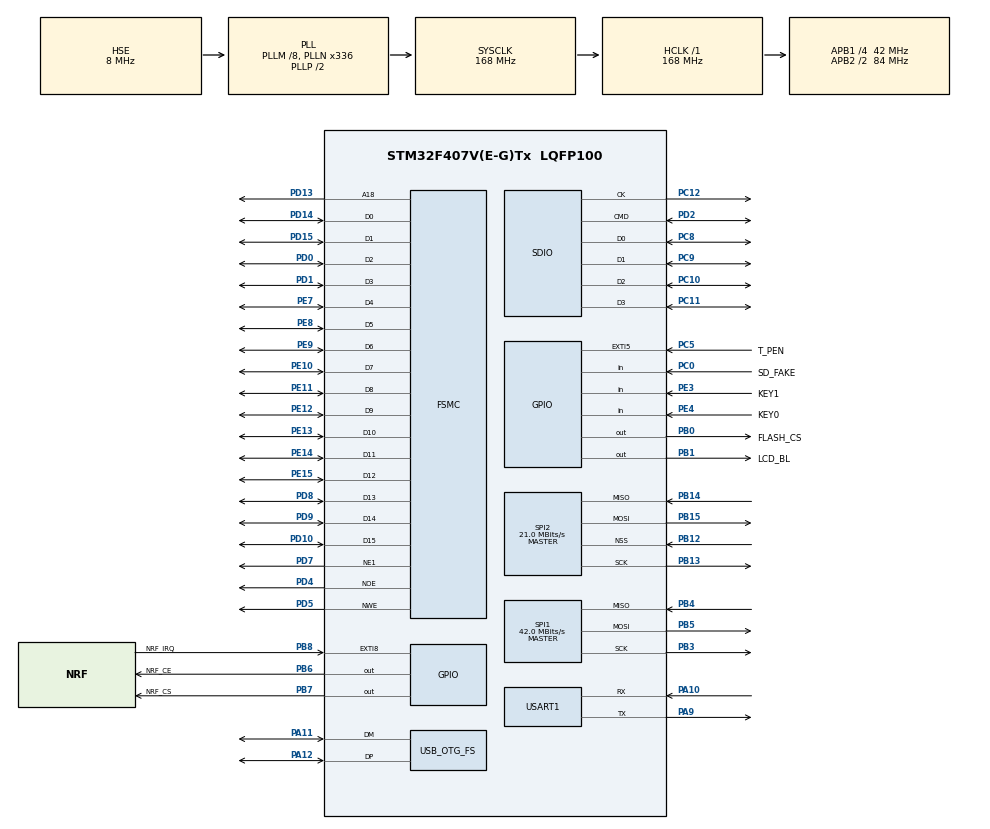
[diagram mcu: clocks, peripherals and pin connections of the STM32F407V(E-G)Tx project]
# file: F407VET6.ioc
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Dma.Request0=SDIO
Dma.SDIO.0.Direction=DMA_PERIPH_TO_MEMORY
Dma.SDIO.0.FIFOMode=DMA_FIFOMODE_ENABLE
Dma.SDIO.0.FIFOThreshold=DMA_FIFO_THRESHOLD_FULL
Dma.SDIO.0.Instance=DMA2_Stream3
Dma.SDIO.0.MemBurst=DMA_MBURST_INC4
Dma.SDIO.0.MemDataAlignment=DMA_MDATAALIGN_WORD
Dma.SDIO.0.MemInc=DMA_MINC_ENABLE
Dma.SDIO.0.Mode=DMA_PFCTRL
Dma.SDIO.0.PeriphBurst=DMA_PBURST_INC4
Dma.SDIO.0.PeriphDataAlignment=DMA_PDATAALIGN_WORD
Dma.SDIO.0.PeriphInc=DMA_PINC_DISABLE
Dma.SDIO.0.Priority=DMA_PRIORITY_LOW
FATFS.BSP.number=1
FATFS0.BSP.STBoard=false
FATFS0.BSP.api=Unknown
FATFS0.BSP.instance=PC0
FATFS0.BSP.ip=GPIO
FATFS0.BSP.mode=Input
FATFS0.BSP.name=Detect_SDIO
FATFS0.BSP.solution=PC0
FSMC.BusTurnAroundDuration1=0
FSMC.DataSetupTime1=13
FSMC.ExtendedMode1=FSMC_EXTENDED_MODE_DISABLE
Mcu.Family=STM32F4
Mcu.Name=STM32F407V(E-G)Tx
Mcu.Package=LQFP100
NVIC.DMA2_Stream3_IRQn=true\:0\:0\:false\:false\:true\:false\:true\:true
NVIC.OTG_FS_IRQn=true\:0\:0\:false\:false\:true\:false\:true\:true
NVIC.PriorityGroup=NVIC_PRIORITYGROUP_4
NVIC.RTC_Alarm_IRQn=true\:0\:0\:false\:false\:true\:true\:true\:true
NVIC.SDIO_IRQn=true\:0\:0\:false\:false\:true\:true\:true\:true
PA10.Mode=Asynchronous
PA10.Signal=USART1_RX
PA11.Mode=Device_Only
PA11.Signal=USB_OTG_FS_DM
PA12.Mode=Device_Only
PA12.Signal=USB_OTG_FS_DP
PA13.Mode=Serial_Wire
PA13.Signal=SYS_JTMS-SWDIO
PA14.Mode=Serial_Wire
PA14.Signal=SYS_JTCK-SWCLK
PA9.Mode=Asynchronous
PA9.Signal=USART1_TX
PB0.GPIO_Label=FLASH_CS
PB0.Signal=GPIO_Output
PB1.GPIO_Label=LCD_BL
PB1.PinState=GPIO_PIN_SET
PB1.Signal=GPIO_Output
PB12.Mode=NSS_Signal_Hard_Input
PB12.Signal=SPI2_NSS
PB13.Mode=Full_Duplex_Master
PB13.Signal=SPI2_SCK
PB14.Mode=Full_Duplex_Master
PB14.Signal=SPI2_MISO
PB15.Mode=Full_Duplex_Master
PB15.Signal=SPI2_MOSI
PB3.Mode=Full_Duplex_Master
PB3.Signal=SPI1_SCK
PB4.Mode=Full_Duplex_Master
PB4.Signal=SPI1_MISO
PB5.Mode=Full_Duplex_Master
PB5.Signal=SPI1_MOSI
PB6.GPIO_Label=NRF_CE
PB6.Signal=GPIO_Output
PB7.GPIO_Label=NRF_CS
PB7.Signal=GPIO_Output
PB8.GPIO_Label=NRF_IRQ
PB8.Signal=GPXTI8
PC0.GPIO_Label=SD_FAKE
PC0.GPIO_PuPd=GPIO_PULLUP
PC0.Signal=GPIO_Input
PC10.Mode=SD_4_bits_Wide_bus
PC10.Signal=SDIO_D2
PC11.Mode=SD_4_bits_Wide_bus
PC11.Signal=SDIO_D3
PC12.Mode=SD_4_bits_Wide_bus
PC12.Signal=SDIO_CK
PC14-OSC32_IN.Mode=LSE-External-Oscillator
PC14-OSC32_IN.Signal=RCC_OSC32_IN
PC15-OSC32_OUT.Mode=LSE-External-Oscillator
PC15-OSC32_OUT.Signal=RCC_OSC32_OUT
PC5.GPIO_Label=T_PEN
PC5.Signal=GPXTI5
PC8.Mode=SD_4_bits_Wide_bus
PC8.Signal=SDIO_D0
PC9.Mode=SD_4_bits_Wide_bus
PC9.Signal=SDIO_D1
PD0.Mode=16b-d1
PD0.Signal=FSMC_D2
PD1.Mode=16b-d1
PD1.Signal=FSMC_D3
PD10.Mode=16b-d1
PD10.Signal=FSMC_D15
PD13.Mode=A18_1
PD13.Signal=FSMC_A18
PD14.Mode=16b-d1
PD14.Signal=FSMC_D0
PD15.Mode=16b-d1
PD15.Signal=FSMC_D1
PD2.Mode=SD_4_bits_Wide_bus
PD2.Signal=SDIO_CMD
PD4.Mode=Lcd1
PD4.Signal=FSMC_NOE
PD5.Mode=Lcd1
PD5.Signal=FSMC_NWE
PD7.Mode=NorPsramChipSelect1_1
PD7.Signal=FSMC_NE1
PD8.Mode=16b-d1
PD8.Signal=FSMC_D13
PD9.Mode=16b-d1
PD9.Signal=FSMC_D14
PE10.Mode=16b-d1
PE10.Signal=FSMC_D7
PE11.Mode=16b-d1
PE11.Signal=FSMC_D8
PE12.Mode=16b-d1
PE12.Signal=FSMC_D9
PE13.Mode=16b-d1
PE13.Signal=FSMC_D10
PE14.Mode=16b-d1
PE14.Signal=FSMC_D11
PE15.Mode=16b-d1
PE15.Signal=FSMC_D12
PE3.GPIO_Label=KEY1
PE3.GPIO_PuPd=GPIO_PULLUP
PE3.Signal=GPIO_Input
PE4.GPIO_Label=KEY0
PE4.GPIO_PuPd=GPIO_PULLUP
PE4.Signal=GPIO_Input
PE7.Mode=16b-d1
PE7.Signal=FSMC_D4
PE8.Mode=16b-d1
PE8.Signal=FSMC_D5
PE9.Mode=16b-d1
PE9.Signal=FSMC_D6
PH0-OSC_IN.Mode=HSE-External-Oscillator
PH0-OSC_IN.Signal=RCC_OSC_IN
PH1-OSC_OUT.Mode=HSE-External-Oscillator
PH1-OSC_OUT.Signal=RCC_OSC_OUT
ProjectManager.HeapSize=0x200
ProjectManager.StackSize=0x400
ProjectManager.TargetToolchain=STM32CubeIDE
RCC.48MHZClocksFreq_Value=48000000
RCC.AHBFreq_Value=168000000
RCC.APB1CLKDivider=RCC_HCLK_DIV4
RCC.APB1Freq_Value=42000000
RCC.APB1TimFreq_Value=84000000
RCC.APB2CLKDivider=RCC_HCLK_DIV2
RCC.APB2Freq_Value=84000000
RCC.APB2TimFreq_Value=168000000
RCC.CortexFreq_Value=168000000
RCC.HCLKFreq_Value=168000000
RCC.HSE_VALUE=8000000
RCC.HSI_VALUE=16000000
RCC.PLLM=8
RCC.PLLN=336
RCC.PLLQ=7
RCC.RCC_RTC_Clock_Source=RCC_RTCCLKSOURCE_LSE
RCC.SYSCLKFreq_VALUE=168000000
RCC.SYSCLKSource=RCC_SYSCLKSOURCE_PLLCLK
RCC.VCOOutputFreq_Value=336000000
RTC.Alarm=RTC_ALARM_A
RTC.Alarm_B=RTC_ALARM_B
SPI1.CalculateBaudRate=42.0 MBits/s
SPI1.Direction=SPI_DIRECTION_2LINES
SPI1.Mode=SPI_MODE_MASTER
SPI1.VirtualType=VM_MASTER
SPI2.CalculateBaudRate=21.0 MBits/s
SPI2.Direction=SPI_DIRECTION_2LINES
SPI2.Mode=SPI_MODE_MASTER
SPI2.VirtualNSS=VM_NSSHARD
SPI2.VirtualType=VM_MASTER
STMicroelectronics.X-CUBE-TOUCHGFX.4.24.0.tgfx_buffering_strategy=Single
STMicroelectronics.X-CUBE-TOUCHGFX.4.24.0.tgfx_custom_height=320
STMicroelectronics.X-CUBE-TOUCHGFX.4.24.0.tgfx_custom_width=240
STMicroelectronics.X-CUBE-TOUCHGFX.4.24.0.tgfx_display_interface=disp_fmc
STMicroelectronics.X-CUBE-TOUCHGFX.4.24.0_IsPackSelfContextualization=true
USART1.VirtualMode=VM_ASYNC
USB_DEVICE.CLASS_NAME_FS=CDC
USB_DEVICE.VirtualMode-CDC_FS=Cdc
USB_DEVICE.VirtualModeFS=Cdc_FS
USB_OTG_FS.VirtualMode=Device_Only
VP_CRC_VS_CRC.Mode=CRC_Activate
VP_FATFS_VS_SDIO.Mode=SDIO
VP_LIBJPEG_VS_JPEGLIB.Mode=Enabled
VP_RTC_VS_RTC_Activate.Mode=RTC_Enabled
VP_RTC_VS_RTC_Alarm_A_Intern.Mode=Alarm A
VP_RTC_VS_RTC_Alarm_B_Intern.Mode=Alarm B
VP_RTC_VS_RTC_Calendar.Mode=RTC_Calendar
VP_USB_DEVICE_VS_USB_DEVICE_CDC_FS.Mode=CDC_FS
board=custom

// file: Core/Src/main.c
/* USER CODE BEGIN Header */
/**
  ******************************************************************************
  * @file           : main.c
  * @brief          : Main program body
  ******************************************************************************
  * @attention
  *
  * Copyright (c) 2024 STMicroelectronics.
  * All rights reserved.
  *
  * This software is licensed under terms that can be found in the LICENSE file
  * in the root directory of this software component.
  * If no LICENSE file comes with this software, it is provided AS-IS.
  *
  ******************************************************************************
  */
/* USER CODE END Header */
#include "main.h"
#include "fatfs.h"
#include "libjpeg.h"
#include "usb_device.h"

/* USER CODE BEGIN Includes */
#include "tft.h"
#include "usbd_cdc_if.h"
/* USER CODE END Includes */

CRC_HandleTypeDef hcrc;

RTC_HandleTypeDef hrtc;

SD_HandleTypeDef hsd;
DMA_HandleTypeDef hdma_sdio;

SPI_HandleTypeDef hspi1;
SPI_HandleTypeDef hspi2;

UART_HandleTypeDef huart1;

SRAM_HandleTypeDef hsram1;

void SystemClock_Config(void);
static void MX_GPIO_Init(void);
static void MX_DMA_Init(void);
static void MX_FSMC_Init(void);
static void MX_RTC_Init(void);
static void MX_SDIO_SD_Init(void);
static void MX_SPI1_Init(void);
static void MX_SPI2_Init(void);
static void MX_USART1_UART_Init(void);
static void MX_CRC_Init(void);

int main(void)
{

  /* MCU Configuration--------------------------------------------------------*/

  /* Reset of all peripherals, Initializes the Flash interface and the Systick. */
  HAL_Init();

  /* Configure the system clock */
  SystemClock_Config();

  /* Initialize all configured peripherals */
  MX_GPIO_Init();
  MX_DMA_Init();
  MX_USB_DEVICE_Init();
  MX_FSMC_Init();
  MX_RTC_Init();
  MX_SDIO_SD_Init();
  MX_SPI1_Init();
  MX_SPI2_Init();
  MX_USART1_UART_Init();
  MX_FATFS_Init();
  MX_LIBJPEG_Init();
  MX_CRC_Init();
  /* USER CODE BEGIN 2 */
  tft_init();
  /* USER CODE END 2 */

  /* Infinite loop */
  /* USER CODE BEGIN WHILE */
  while (1)
  {
	printf("hello World \n");
    /* USER CODE END WHILE */

    /* USER CODE BEGIN 3 */
	transmit_from_buffer();
  }
  /* USER CODE END 3 */
}

void SystemClock_Config(void)
{
  RCC_OscInitTypeDef RCC_OscInitStruct = {0};
  RCC_ClkInitTypeDef RCC_ClkInitStruct = {0};

  /** Configure the main internal regulator output voltage
  */
  __HAL_RCC_PWR_CLK_ENABLE();
  __HAL_PWR_VOLTAGESCALING_CONFIG(PWR_REGULATOR_VOLTAGE_SCALE1);

  /** Initializes the RCC Oscillators according to the specified parameters
  * in the RCC_OscInitTypeDef structure.
  */
  RCC_OscInitStruct.OscillatorType = RCC_OSCILLATORTYPE_HSE|RCC_OSCILLATORTYPE_LSE;
  RCC_OscInitStruct.HSEState = RCC_HSE_ON;
  RCC_OscInitStruct.LSEState = RCC_LSE_ON;
  RCC_OscInitStruct.PLL.PLLState = RCC_PLL_ON;
  RCC_OscInitStruct.PLL.PLLSource = RCC_PLLSOURCE_HSE;
  RCC_OscInitStruct.PLL.PLLM = 8;
  RCC_OscInitStruct.PLL.PLLN = 336;
  RCC_OscInitStruct.PLL.PLLP = RCC_PLLP_DIV2;
  RCC_OscInitStruct.PLL.PLLQ = 7;
  if (HAL_RCC_OscConfig(&RCC_OscInitStruct) != HAL_OK)
  {
    Error_Handler();
  }

  /** Initializes the CPU, AHB and APB buses clocks
  */
  RCC_ClkInitStruct.ClockType = RCC_CLOCKTYPE_HCLK|RCC_CLOCKTYPE_SYSCLK
                              |RCC_CLOCKTYPE_PCLK1|RCC_CLOCKTYPE_PCLK2;
  RCC_ClkInitStruct.SYSCLKSource = RCC_SYSCLKSOURCE_PLLCLK;
  RCC_ClkInitStruct.AHBCLKDivider = RCC_SYSCLK_DIV1;
  RCC_ClkInitStruct.APB1CLKDivider = RCC_HCLK_DIV4;
  RCC_ClkInitStruct.APB2CLKDivider = RCC_HCLK_DIV2;

  if (HAL_RCC_ClockConfig(&RCC_ClkInitStruct, FLASH_LATENCY_5) != HAL_OK)
  {
    Error_Handler();
  }
}

static void MX_CRC_Init(void)
{

  hcrc.Instance = CRC;
  if (HAL_CRC_Init(&hcrc) != HAL_OK)
  {
    Error_Handler();
  }

}

static void MX_RTC_Init(void)
{

  RTC_TimeTypeDef sTime = {0};
  RTC_DateTypeDef sDate = {0};
  RTC_AlarmTypeDef sAlarm = {0};

  /** Initialize RTC Only
  */
  hrtc.Instance = RTC;
  hrtc.Init.HourFormat = RTC_HOURFORMAT_24;
  hrtc.Init.AsynchPrediv = 127;
  hrtc.Init.SynchPrediv = 255;
  hrtc.Init.OutPut = RTC_OUTPUT_DISABLE;
  hrtc.Init.OutPutPolarity = RTC_OUTPUT_POLARITY_HIGH;
  hrtc.Init.OutPutType = RTC_OUTPUT_TYPE_OPENDRAIN;
  if (HAL_RTC_Init(&hrtc) != HAL_OK)
  {
    Error_Handler();
  }

  /** Initialize RTC and set the Time and Date
  */
  sTime.Hours = 0x0;
  sTime.Minutes = 0x0;
  sTime.Seconds = 0x0;
  sTime.DayLightSaving = RTC_DAYLIGHTSAVING_NONE;
  sTime.StoreOperation = RTC_STOREOPERATION_RESET;
  if (HAL_RTC_SetTime(&hrtc, &sTime, RTC_FORMAT_BCD) != HAL_OK)
  {
    Error_Handler();
  }
  sDate.WeekDay = RTC_WEEKDAY_MONDAY;
  sDate.Month = RTC_MONTH_JANUARY;
  sDate.Date = 0x1;
  sDate.Year = 0x0;

  if (HAL_RTC_SetDate(&hrtc, &sDate, RTC_FORMAT_BCD) != HAL_OK)
  {
    Error_Handler();
  }

  /** Enable the Alarm A
  */
  sAlarm.AlarmTime.Hours = 0x0;
  sAlarm.AlarmTime.Minutes = 0x0;
  sAlarm.AlarmTime.Seconds = 0x0;
  sAlarm.AlarmTime.SubSeconds = 0x0;
  sAlarm.AlarmTime.DayLightSaving = RTC_DAYLIGHTSAVING_NONE;
  sAlarm.AlarmTime.StoreOperation = RTC_STOREOPERATION_RESET;
  sAlarm.AlarmMask = RTC_ALARMMASK_NONE;
  sAlarm.AlarmSubSecondMask = RTC_ALARMSUBSECONDMASK_ALL;
  sAlarm.AlarmDateWeekDaySel = RTC_ALARMDATEWEEKDAYSEL_DATE;
  sAlarm.AlarmDateWeekDay = 0x1;
  sAlarm.Alarm = RTC_ALARM_A;
  if (HAL_RTC_SetAlarm_IT(&hrtc, &sAlarm, RTC_FORMAT_BCD) != HAL_OK)
  {
    Error_Handler();
  }

  /** Enable the Alarm B
  */
  sAlarm.Alarm = RTC_ALARM_B;
  if (HAL_RTC_SetAlarm_IT(&hrtc, &sAlarm, RTC_FORMAT_BCD) != HAL_OK)
  {
    Error_Handler();
  }

}

static void MX_SDIO_SD_Init(void)
{

  hsd.Instance = SDIO;
  hsd.Init.ClockEdge = SDIO_CLOCK_EDGE_RISING;
  hsd.Init.ClockBypass = SDIO_CLOCK_BYPASS_DISABLE;
  hsd.Init.ClockPowerSave = SDIO_CLOCK_POWER_SAVE_DISABLE;
  hsd.Init.BusWide = SDIO_BUS_WIDE_4B;
  hsd.Init.HardwareFlowControl = SDIO_HARDWARE_FLOW_CONTROL_DISABLE;
  hsd.Init.ClockDiv = 0;

}

static void MX_SPI1_Init(void)
{

  /* SPI1 parameter configuration*/
  hspi1.Instance = SPI1;
  hspi1.Init.Mode = SPI_MODE_MASTER;
  hspi1.Init.Direction = SPI_DIRECTION_2LINES;
  hspi1.Init.DataSize = SPI_DATASIZE_8BIT;
  hspi1.Init.CLKPolarity = SPI_POLARITY_LOW;
  hspi1.Init.CLKPhase = SPI_PHASE_1EDGE;
  hspi1.Init.NSS = SPI_NSS_SOFT;
  hspi1.Init.BaudRatePrescaler = SPI_BAUDRATEPRESCALER_2;
  hspi1.Init.FirstBit = SPI_FIRSTBIT_MSB;
  hspi1.Init.TIMode = SPI_TIMODE_DISABLE;
  hspi1.Init.CRCCalculation = SPI_CRCCALCULATION_DISABLE;
  hspi1.Init.CRCPolynomial = 10;
  if (HAL_SPI_Init(&hspi1) != HAL_OK)
  {
    Error_Handler();
  }

}

static void MX_SPI2_Init(void)
{

  /* SPI2 parameter configuration*/
  hspi2.Instance = SPI2;
  hspi2.Init.Mode = SPI_MODE_MASTER;
  hspi2.Init.Direction = SPI_DIRECTION_2LINES;
  hspi2.Init.DataSize = SPI_DATASIZE_8BIT;
  hspi2.Init.CLKPolarity = SPI_POLARITY_LOW;
  hspi2.Init.CLKPhase = SPI_PHASE_1EDGE;
  hspi2.Init.NSS = SPI_NSS_HARD_INPUT;
  hspi2.Init.BaudRatePrescaler = SPI_BAUDRATEPRESCALER_2;
  hspi2.Init.FirstBit = SPI_FIRSTBIT_MSB;
  hspi2.Init.TIMode = SPI_TIMODE_DISABLE;
  hspi2.Init.CRCCalculation = SPI_CRCCALCULATION_DISABLE;
  hspi2.Init.CRCPolynomial = 10;
  if (HAL_SPI_Init(&hspi2) != HAL_OK)
  {
    Error_Handler();
  }

}

static void MX_USART1_UART_Init(void)
{

  huart1.Instance = USART1;
  huart1.Init.BaudRate = 115200;
  huart1.Init.WordLength = UART_WORDLENGTH_8B;
  huart1.Init.StopBits = UART_STOPBITS_1;
  huart1.Init.Parity = UART_PARITY_NONE;
  huart1.Init.Mode = UART_MODE_TX_RX;
  huart1.Init.HwFlowCtl = UART_HWCONTROL_NONE;
  huart1.Init.OverSampling = UART_OVERSAMPLING_16;
  if (HAL_UART_Init(&huart1) != HAL_OK)
  {
    Error_Handler();
  }

}

static void MX_DMA_Init(void)
{

  /* DMA controller clock enable */
  __HAL_RCC_DMA2_CLK_ENABLE();

  /* DMA interrupt init */
  /* DMA2_Stream3_IRQn interrupt configuration */
  HAL_NVIC_SetPriority(DMA2_Stream3_IRQn, 0, 0);
  HAL_NVIC_EnableIRQ(DMA2_Stream3_IRQn);

}

static void MX_GPIO_Init(void)
{
  GPIO_InitTypeDef GPIO_InitStruct = {0};

  /* GPIO Ports Clock Enable */
  __HAL_RCC_GPIOE_CLK_ENABLE();
  __HAL_RCC_GPIOC_CLK_ENABLE();
  __HAL_RCC_GPIOH_CLK_ENABLE();
  __HAL_RCC_GPIOB_CLK_ENABLE();
  __HAL_RCC_GPIOD_CLK_ENABLE();
  __HAL_RCC_GPIOA_CLK_ENABLE();

  /*Configure GPIO pin Output Level */
  HAL_GPIO_WritePin(GPIOB, FLASH_CS_Pin|NRF_CE_Pin|NRF_CS_Pin, GPIO_PIN_RESET);

  /*Configure GPIO pin Output Level */
  HAL_GPIO_WritePin(LCD_BL_GPIO_Port, LCD_BL_Pin, GPIO_PIN_SET);

  /*Configure GPIO pins : KEY1_Pin KEY0_Pin */
  GPIO_InitStruct.Pin = KEY1_Pin|KEY0_Pin;
  GPIO_InitStruct.Mode = GPIO_MODE_INPUT;
  GPIO_InitStruct.Pull = GPIO_PULLUP;
  HAL_GPIO_Init(GPIOE, &GPIO_InitStruct);

  /*Configure GPIO pin : SD_FAKE_Pin */
  GPIO_InitStruct.Pin = SD_FAKE_Pin;
  GPIO_InitStruct.Mode = GPIO_MODE_INPUT;
  GPIO_InitStruct.Pull = GPIO_PULLUP;
  HAL_GPIO_Init(SD_FAKE_GPIO_Port, &GPIO_InitStruct);

  /*Configure GPIO pin : T_PEN_Pin */
  GPIO_InitStruct.Pin = T_PEN_Pin;
  GPIO_InitStruct.Mode = GPIO_MODE_IT_RISING;
  GPIO_InitStruct.Pull = GPIO_NOPULL;
  HAL_GPIO_Init(T_PEN_GPIO_Port, &GPIO_InitStruct);

  /*Configure GPIO pins : FLASH_CS_Pin LCD_BL_Pin NRF_CE_Pin NRF_CS_Pin */
  GPIO_InitStruct.Pin = FLASH_CS_Pin|LCD_BL_Pin|NRF_CE_Pin|NRF_CS_Pin;
  GPIO_InitStruct.Mode = GPIO_MODE_OUTPUT_PP;
  GPIO_InitStruct.Pull = GPIO_NOPULL;
  GPIO_InitStruct.Speed = GPIO_SPEED_FREQ_LOW;
  HAL_GPIO_Init(GPIOB, &GPIO_InitStruct);

  /*Configure GPIO pin : NRF_IRQ_Pin */
  GPIO_InitStruct.Pin = NRF_IRQ_Pin;
  GPIO_InitStruct.Mode = GPIO_MODE_IT_RISING;
  GPIO_InitStruct.Pull = GPIO_NOPULL;
  HAL_GPIO_Init(NRF_IRQ_GPIO_Port, &GPIO_InitStruct);

}

/* FSMC initialization function */
static void MX_FSMC_Init(void)
{

  FSMC_NORSRAM_TimingTypeDef Timing = {0};

  /** Perform the SRAM1 memory initialization sequence
  */
  hsram1.Instance = FSMC_NORSRAM_DEVICE;
  hsram1.Extended = FSMC_NORSRAM_EXTENDED_DEVICE;
  /* hsram1.Init */
  hsram1.Init.NSBank = FSMC_NORSRAM_BANK1;
  hsram1.Init.DataAddressMux = FSMC_DATA_ADDRESS_MUX_DISABLE;
  hsram1.Init.MemoryType = FSMC_MEMORY_TYPE_SRAM;
  hsram1.Init.MemoryDataWidth = FSMC_NORSRAM_MEM_BUS_WIDTH_16;
  hsram1.Init.BurstAccessMode = FSMC_BURST_ACCESS_MODE_DISABLE;
  hsram1.Init.WaitSignalPolarity = FSMC_WAIT_SIGNAL_POLARITY_LOW;
  hsram1.Init.WrapMode = FSMC_WRAP_MODE_DISABLE;
  hsram1.Init.WaitSignalActive = FSMC_WAIT_TIMING_BEFORE_WS;
  hsram1.Init.WriteOperation = FSMC_WRITE_OPERATION_ENABLE;
  hsram1.Init.WaitSignal = FSMC_WAIT_SIGNAL_DISABLE;
  hsram1.Init.ExtendedMode = FSMC_EXTENDED_MODE_DISABLE;
  hsram1.Init.AsynchronousWait = FSMC_ASYNCHRONOUS_WAIT_DISABLE;
  hsram1.Init.WriteBurst = FSMC_WRITE_BURST_DISABLE;
  hsram1.Init.PageSize = FSMC_PAGE_SIZE_NONE;
  /* Timing */
  Timing.AddressSetupTime = 15;
  Timing.AddressHoldTime = 15;
  Timing.DataSetupTime = 13;
  Timing.BusTurnAroundDuration = 0;
  Timing.CLKDivision = 16;
  Timing.DataLatency = 17;
  Timing.AccessMode = FSMC_ACCESS_MODE_A;
  /* ExtTiming */

  if (HAL_SRAM_Init(&hsram1, &Timing, NULL) != HAL_OK)
  {
    Error_Handler( );
  }

}

void Error_Handler(void)
{
  __disable_irq();
  while (1)
  {
  }
}
